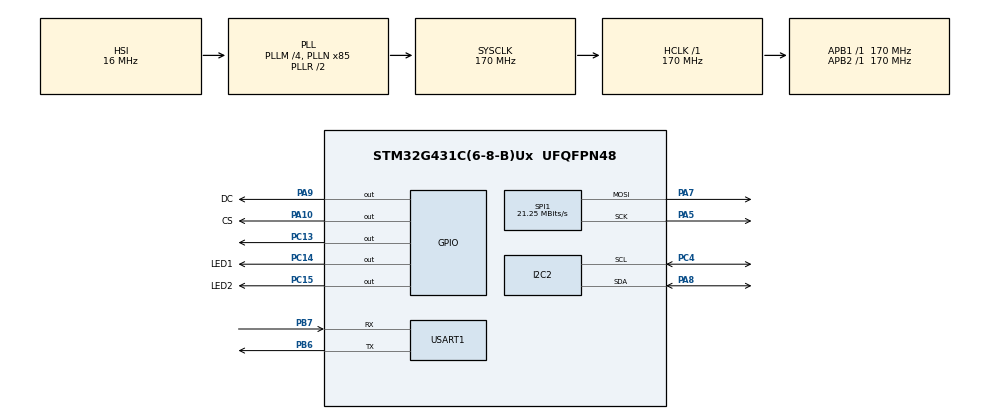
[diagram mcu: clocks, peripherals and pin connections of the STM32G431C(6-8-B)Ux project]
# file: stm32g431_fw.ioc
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I2C2.Timing=0x40B285C2
Mcu.Family=STM32G4
Mcu.Name=STM32G431C(6-8-B)Ux
Mcu.Package=UFQFPN48
NVIC.PriorityGroup=NVIC_PRIORITYGROUP_4
PA10.GPIO_Label=CS
PA10.GPIO_Speed=GPIO_SPEED_FREQ_HIGH
PA10.Signal=GPIO_Output
PA13.Mode=Serial_Wire
PA13.Signal=SYS_JTMS-SWDIO
PA14.Mode=Serial_Wire
PA14.Signal=SYS_JTCK-SWCLK
PA5.Mode=TX_Only_Simplex_Unidirect_Master
PA5.Signal=SPI1_SCK
PA7.Mode=TX_Only_Simplex_Unidirect_Master
PA7.Signal=SPI1_MOSI
PA8.Mode=I2C
PA8.Signal=I2C2_SDA
PA9.GPIO_Label=DC
PA9.GPIO_Speed=GPIO_SPEED_FREQ_HIGH
PA9.Signal=GPIO_Output
PB6.Mode=Asynchronous
PB6.Signal=USART1_TX
PB7.Mode=Asynchronous
PB7.Signal=USART1_RX
PC13.Signal=GPIO_Output
PC14-OSC32_IN.GPIO_Label=LED1
PC14-OSC32_IN.Signal=GPIO_Output
PC15-OSC32_OUT.GPIO_Label=LED2
PC15-OSC32_OUT.Signal=GPIO_Output
PC4.Mode=I2C
PC4.Signal=I2C2_SCL
PF0-OSC_IN.Mode=HSE-External-Oscillator
PF0-OSC_IN.Signal=RCC_OSC_IN
PF1-OSC_OUT.Mode=HSE-External-Oscillator
PF1-OSC_OUT.Signal=RCC_OSC_OUT
ProjectManager.HeapSize=0x200
ProjectManager.StackSize=0x400
ProjectManager.TargetToolchain=STM32CubeIDE
RCC.ADC12Freq_Value=170000000
RCC.AHBFreq_Value=170000000
RCC.APB1Freq_Value=170000000
RCC.APB1TimFreq_Value=170000000
RCC.APB2Freq_Value=170000000
RCC.APB2TimFreq_Value=170000000
RCC.CortexFreq_Value=170000000
RCC.EXTERNAL_CLOCK_VALUE=12288000
RCC.HCLKFreq_Value=170000000
RCC.HSE_VALUE=8000000
RCC.HSI48_VALUE=48000000
RCC.HSI_VALUE=16000000
RCC.LSE_VALUE=32768
RCC.PLLM=RCC_PLLM_DIV4
RCC.PLLN=85
RCC.SYSCLKFreq_VALUE=170000000
RCC.SYSCLKSource=RCC_SYSCLKSOURCE_PLLCLK
RCC.USBFreq_Value=170000000
RCC.VCOOutputFreq_Value=340000000
SPI1.BaudRatePrescaler=SPI_BAUDRATEPRESCALER_8
SPI1.CalculateBaudRate=21.25 MBits/s
SPI1.DataSize=SPI_DATASIZE_8BIT
SPI1.Direction=SPI_DIRECTION_2LINES
SPI1.Mode=SPI_MODE_MASTER
SPI1.VirtualType=VM_MASTER
USART1.VirtualMode-Asynchronous=VM_ASYNC
VP_SYS_VS_DBSignals.Mode=DisableDeadBatterySignals
board=custom

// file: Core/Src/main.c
/* USER CODE BEGIN Header */
/**
  ******************************************************************************
  * @file           : main.c
  * @brief          : Main program body
  ******************************************************************************
  * @attention
  *
  * Copyright (c) 2025 STMicroelectronics.
  * All rights reserved.
  *
  * This software is licensed under terms that can be found in the LICENSE file
  * in the root directory of this software component.
  * If no LICENSE file comes with this software, it is provided AS-IS.
  *
  ******************************************************************************
  */
/* USER CODE END Header */
#include "main.h"
#include "i2c.h"
#include "spi.h"
#include "usart.h"
#include "gpio.h"

/* USER CODE BEGIN Includes */
#include <stdint.h>
#include <stdio.h>
#include "st7789.h"
#include "st7789_font.h"
/* USER CODE END Includes */

void SystemClock_Config(void);

/* USER CODE BEGIN 0 */
char buf[32];
/* USER CODE END 0 */

int main(void)
{

  /* MCU Configuration--------------------------------------------------------*/

  /* Reset of all peripherals, Initializes the Flash interface and the Systick. */
  HAL_Init();

  /* Configure the system clock */
  SystemClock_Config();

  /* Initialize all configured peripherals */
  MX_GPIO_Init();
  MX_SPI1_Init();
  MX_I2C2_Init();
  MX_USART1_UART_Init();
  /* USER CODE BEGIN 2 */
  ST7789_Init();
  /* USER CODE END 2 */

  /* Infinite loop */
  while (1)
  {
    ST7789_FillRect(0,0,320,240,COLOR_WHITE);
    snprintf(buf, sizeof(buf), "st7789 test!!!");
    st7789_write_string(0, 30, font6x8, buf, COLOR_RED, COLOR_WHITE);
    HAL_Delay(2000);
  }
}

void SystemClock_Config(void)
{
  RCC_OscInitTypeDef RCC_OscInitStruct = {0};
  RCC_ClkInitTypeDef RCC_ClkInitStruct = {0};

  /** Configure the main internal regulator output voltage
  */
  HAL_PWREx_ControlVoltageScaling(PWR_REGULATOR_VOLTAGE_SCALE1_BOOST);

  /** Initializes the RCC Oscillators according to the specified parameters
  * in the RCC_OscInitTypeDef structure.
  */
  RCC_OscInitStruct.OscillatorType = RCC_OSCILLATORTYPE_HSI;
  RCC_OscInitStruct.HSIState = RCC_HSI_ON;
  RCC_OscInitStruct.HSICalibrationValue = RCC_HSICALIBRATION_DEFAULT;
  RCC_OscInitStruct.PLL.PLLState = RCC_PLL_ON;
  RCC_OscInitStruct.PLL.PLLSource = RCC_PLLSOURCE_HSI;
  RCC_OscInitStruct.PLL.PLLM = RCC_PLLM_DIV4;
  RCC_OscInitStruct.PLL.PLLN = 85;
  RCC_OscInitStruct.PLL.PLLP = RCC_PLLP_DIV2;
  RCC_OscInitStruct.PLL.PLLQ = RCC_PLLQ_DIV2;
  RCC_OscInitStruct.PLL.PLLR = RCC_PLLR_DIV2;
  if (HAL_RCC_OscConfig(&RCC_OscInitStruct) != HAL_OK)
  {
    Error_Handler();
  }

  /** Initializes the CPU, AHB and APB buses clocks
  */
  RCC_ClkInitStruct.ClockType = RCC_CLOCKTYPE_HCLK|RCC_CLOCKTYPE_SYSCLK
                              |RCC_CLOCKTYPE_PCLK1|RCC_CLOCKTYPE_PCLK2;
  RCC_ClkInitStruct.SYSCLKSource = RCC_SYSCLKSOURCE_PLLCLK;
  RCC_ClkInitStruct.AHBCLKDivider = RCC_SYSCLK_DIV1;
  RCC_ClkInitStruct.APB1CLKDivider = RCC_HCLK_DIV1;
  RCC_ClkInitStruct.APB2CLKDivider = RCC_HCLK_DIV1;

  if (HAL_RCC_ClockConfig(&RCC_ClkInitStruct, FLASH_LATENCY_4) != HAL_OK)
  {
    Error_Handler();
  }
}

void Error_Handler(void)
{
  __disable_irq();
  while (1)
  {
  }
}
